# DA1470x register map
Vendor: Dialog; Series: DA1470x; File version: 1.2
CPU: CM33 r0p2, little endian, MPU, FPU, DSP, VTOR, 4 interrupt priority bits
Registers are 32-bit, read-write, reset 0x0 unless marked. A register's access mark holds for its fields unless they carry their own. Offsets are from the block's base; [hi:lo] are bit positions; {n}, {i} and the like mark numbered series; <NAME> marks a mode.

## CRG_TOP — CRG_TOP registers
Base 0x50000000
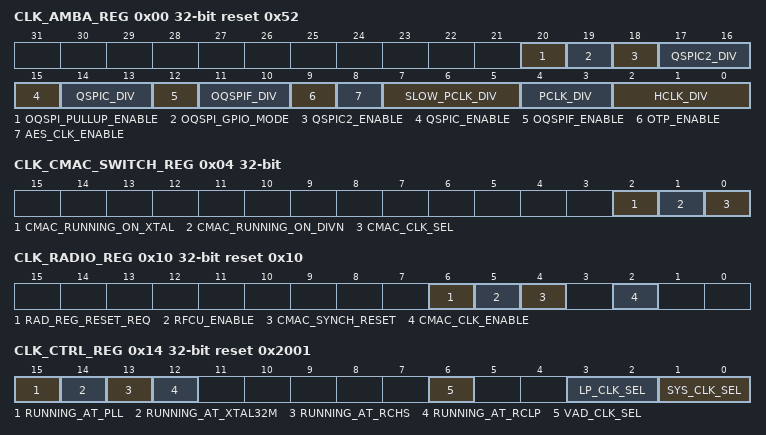
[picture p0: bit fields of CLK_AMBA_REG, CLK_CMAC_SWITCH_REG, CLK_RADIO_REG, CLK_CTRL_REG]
0x00 CLK_AMBA_REG reset 0x52 — HCLK, PCLK, divider and clock gates
  [20] OQSPI_PULLUP_ENABLE — Selects pull value when OQSPIF_D* pads are not output. 0: The pads are pull-down 1: The pads are pull-up (to V18F)
  [19] OQSPI_GPIO_MODE — If this bit is set, the upper 4 pins of the OQSPIF controller can be used as GPIO, P2_07 to P2_04. In this mode, the OQSPIF controller should be restricted to QUAD mode or less. Note: the supply remains V18F, so if the supply is off, the pads become floating.
  [18] QSPIC2_ENABLE — Clock enable for QSPI RAM controller
  [17:16] QSPIC2_DIV — Clock divider setting. 0b00: divide by 1 0b01: divide by 2 0b10: divide by 4 0b11: divide by 8
  [15] QSPIC_ENABLE — Clock enable for QSPI FLASH2 controller
  [14:13] QSPIC_DIV — Clock divider setting. 0b00: divide by 1 0b01: divide by 2 0b10: divide by 4 0b11: divide by 8
  [12] OQSPIF_ENABLE — Clock enable for Octal SPI controller
  [11:10] OQSPIF_DIV — Clock divider setting. 0b00: divide by 1 0b01: divide by 2 0b10: divide by 4 0b11: divide by 8
  [9] OTP_ENABLE — Clock enable for OTP controller
  [8] AES_CLK_ENABLE — Clock enable for AES crypto block
  [7:5] SLOW_PCLK_DIV — Slow-APB interface clock, derived from DIVN_CLK: 0b000: divide divn_clk by 1 0b001: divide divn_clk by 2 0b010: divide divn_clk by 4 0b011: divide divn_clk by 8 0b1xx: divide divn_clk by 16
  [4:3] PCLK_DIV — Fast-APB interface clock, Cascaded with HCLK: 0b00: divide hclk by 1 0b01: divide hclk by 2 0b10: divide hclk by 4 0b11: divide hclk by 8
  [2:0] HCLK_DIV — AHB interface and microprocessor clock. Source clock divided by: 0b000: divide clk by 1 0b001: divide clk by 2 0b010: divide clk by 4 0b011: divide clk by 8 0b1xx: divide clk by 16
0x04 CLK_CMAC_SWITCH_REG — Clock switching register for CMAC clock domain
  [2] CMAC_RUNNING_ON_XTAL ro — This bit is '1' when the CMAC_CLK is enabled, and the switch is set in the XTAL32M position.
  [1] CMAC_RUNNING_ON_DIVN ro — This bit is '1' when the CMAC_CLK is enabled, and the switch is set in the DIVN_CLK position.
  [0] CMAC_CLK_SEL — Selects the clock source of the CMAC_CLK. 0: DIVN_CLK is selected 1: XTAL32M is selected. Note: this bitfield can only be set to '1' when the PD_RAD domain is on (RAD_IS_UP), and will be automatically reset to '0' when the PD_RAD power domain turns off.
0x0C RST_CTRL_REG — Reset control register
  [0] SYS_CACHE_FLUSH_WITH_SW_RESET — 0: Flush the System Cache memory only at HW reset. 1: Flush the System Cache memory also at SW reset.
0x10 CLK_RADIO_REG reset 0x10 — Radio PLL control register
  [6] RAD_REG_RESET_REQ — Reset request for registers of the radio PHY.
  [5] RFCU_ENABLE — Enable the RF control Unit clock
  [4] CMAC_SYNCH_RESET — Force synchronous reset to CMAC core and Sleep Timer. Its effective only when both Radio and Timer Power Domains are powered and the clocks are enabled. CMAC CPU and CMAC registers, including the retained ones, will be reset. It should be kept in reset for enough time to make sure that it will be captured by CMAC, Low Power and APB clocks.
  [2] CMAC_CLK_ENABLE — Enables the clock
0x14 CLK_CTRL_REG reset 0x2001 — Clock control register
  [15] RUNNING_AT_PLL ro — Indicates that the PLL clock is used as clock, and may not be switched off
  [14] RUNNING_AT_XTAL32M ro — Indicates that the XTAL32M clock is used as clock, and may not be switched off
  [13] RUNNING_AT_RCHS ro — Indicates that the RCHS clock is used as clock
  [12] RUNNING_AT_RCLP ro — Indicates that the RCLP_CLK is being used as clock
  [6] VAD_CLK_SEL — Selects the clock for the VAD. 0: Select RCLP clock (normalized for ~32KHz) 1: Select XTAL32K
  [3:2] LP_CLK_SEL — Sets the clock source of the LowerPower clock 0x0: RC32K 0x1: RCX 0x2: XTAL32K through the oscillator with an external Crystal. 0x3: XTAL32K through an external square wave generator (set PID of GPIO to FUNC_GPIO)
  [1:0] SYS_CLK_SEL — Selects the clock source. 0x0 : XTAL32M 0x1 : RCHS 0x2 : The Low Power clock is used 0x3 : The PLL160Mhz is used Note: switching to/from PLL may only be done from/to XTAL32M.
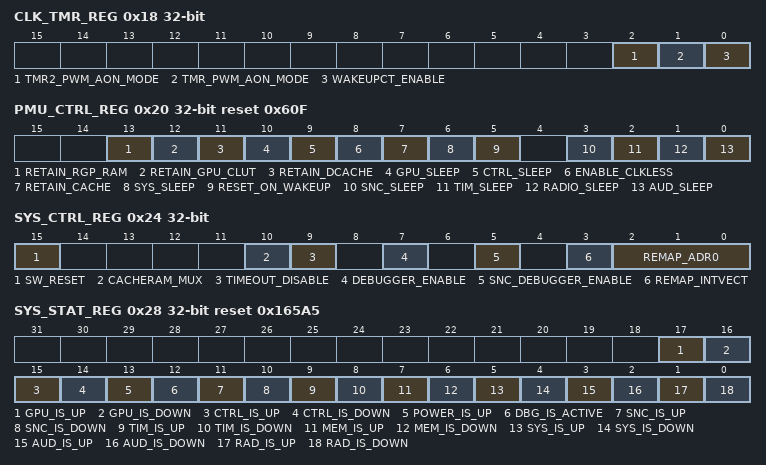
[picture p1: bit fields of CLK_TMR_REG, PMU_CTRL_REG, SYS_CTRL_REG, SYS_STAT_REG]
0x18 CLK_TMR_REG — Clock control for the timers
  [2] TMR2_PWM_AON_MODE — Maps Timer2_pwm onto P1_17. This state is preserved during deep sleep, to allow PWM output on the pad during deep sleep.
  [1] TMR_PWM_AON_MODE — Maps Timer1_pwm onto P1_00 This state is preserved during deep sleep, to allow PWM output on the pad during deep sleep.
  [0] WAKEUPCT_ENABLE — Enables the clock
0x1C CLK_SWITCH2XTAL_REG — Switches clock from RC32M to XTAL32M
  [0] SWITCH2XTAL wo — When writing to this register, the clock switch will happen from RC32M to XTAL32M. If any other clock is selected than RC32M, the selection is discarded.
0x20 PMU_CTRL_REG reset 0x60F — Power Management Unit control register
  [13] RETAIN_RGP_RAM — Retain the R-G-B RAMs inside the LCD display controller
  [12] RETAIN_GPU_CLUT — Retain the GPU CLUT memory
  [11] RETAIN_DCACHE — Selects the retainability of the dcache block while PD_CTRL is off. '1' is retainable, '0' is power gated
  [10] GPU_SLEEP — Put the GPU power domain (PD_GPU) in powerdown
  [9] CTRL_SLEEP — Put the Controller power domain (PD_CTRL) in powerdown
  [8] ENABLE_CLKLESS — Selects the clockless sleep mode. Wakeup is done asynchronously. When set to '1', the lp_clk is stopped during deep sleep, until a wakeup event (not debounced) is detected by the WAKUPCT block. When set to '0', the lp_clk continues running, so the MAC counters keep on running. This mode cannot be combined with regulated sleep, so keep SLEEP_TIMER=0 when using ENABLE_CLKLESS.
  [7] RETAIN_CACHE — Selects the retainability of the cache block during deep sleep. '1' is retainable, '0' is power gated
  [6] SYS_SLEEP — Put the System powerdomain (PD_SYS) in powerdown. If this bit is '1', and there is no pending IRQ in the PDC for the M33, the PD_SYS will be switched off. Wakeup should be handled by the PDC.
  [5] RESET_ON_WAKEUP — Perform a Hardware Reset after waking up. Booter will be started.
  [3] SNC_SLEEP — Put the Communications powerdomain (PD_SNC) in powerdown
  [2] TIM_SLEEP — Put the Timers Powerdomain (PD_TIM) in powerdown.
  [1] RADIO_SLEEP — Put the digital part of the radio, including CMAC (PD_RAD) in powerdown
  [0] AUD_SLEEP — Put the audio power domain (PD_AUD) in powerdown
0x24 SYS_CTRL_REG — System Control register
  [15] SW_RESET wo — Writing a '1' to this bit will generate a SW_RESET.
  [10] CACHERAM_MUX — Controls accessiblity of Cache RAM: 0: the cache controller is bypassed, the cacheRAM is visible in the memory space 1: the cache controller is enabled, the cacheRAM is not visible anymore in the memory space
  [9] TIMEOUT_DISABLE — Disables timeout in Power statemachine. By default, the statemachine continues if after 2 ms the blocks are not started up. This can be read back from ANA_STATUS_REG
  [7] DEBUGGER_ENABLE — Enable the debugger. This bit is set by the booter according to the OTP header. If not set, the SWDIO and SW_CLK can be used as gpio ports.
  [5] SNC_DEBUGGER_ENABLE — Enable the CMAC debugger. If not set, the SWDIO and SW_CLK can be used as gpio ports.
  [3] REMAP_INTVECT — 0: normal operation 1: If ARM is in address range 0 to 0x1FF then the address is remapped to SYS-RAM 0x0080.0000 to 0x0080.01FF. This allows to put the interrupt vector table to be placed in RAM while executing from QSPI.
  [2:0] REMAP_ADR0 — Controls which memory is located at address 0x0000 for execution. 0x0: ROM 0x1: OTP un-cached 0x2: OQSPI FLASH cached (see also the CACHE_FLASH_REG.FLASH_REGION.* descriptions) Note 1: When REMAP_ADR0=0x2, address 0x0 is mapped to FLASH_REGION_BASE + FLASH_REGION_OFFSET<<2. Note 2: When REMAP_ADR0=0x2, the CPU can only access the Flash region [FLASH_REGION_BASE + FLASH_REGION_OFFSET<<2, FLASH_REGION_SIZE] from the 0x16000000 address range. The complete Flash can be accessed via the 0x36000000 address range but only uncached. 0x3: RAMS un-cached 0x4: OQSPI FLASH un-cached (for verification only) 0x5: SYSRAM3 (for SNC-based applications, where SNC uses SYSRAM 1&2) 0x6: Cache Data RAM un-cached (CACHERAM_MUX=0, for testing purposes only) Note 1: DWord (64 bits) access is not supported by the Cache Data RAM interface in mirrored mode (only 32, 16 and 8 bits). Note 2: DMA access is not supported by the Cache Data RAM interface when REMAP_ADR0=0x6.
0x28 SYS_STAT_REG reset 0x165A5 — System status register
  [17] GPU_IS_UP ro — Indicates that PD_GPU is functional
  [16] GPU_IS_DOWN ro — Indicates that PD_GPU is in power down
  [15] CTRL_IS_UP ro — Indicates that PD_CTRL is functional
  [14] CTRL_IS_DOWN ro — Indicates that PD_CTRL is in power down
  [13] POWER_IS_UP ro — Indicates that the Startup statemachine is finished, and all power regulation is in order. In UltraFastWakeup mode, the SW needs to wait for this signal before starting any heavy traffic.
  [12] DBG_IS_ACTIVE ro — Indicates that a debugger is attached.
  [11] SNC_IS_UP ro — Indicates that PD_SNC is functional
  [10] SNC_IS_DOWN ro — Indicates that PD_SNC is in power down
  [9] TIM_IS_UP ro — Indicates that PD_TIM is functional
  [8] TIM_IS_DOWN ro — Indicates that PD_TIM is in power down
  [7] MEM_IS_UP ro — Indicates that PD_MEM is functional
  [6] MEM_IS_DOWN ro — Indicates that PD_MEM is in power down
  [5] SYS_IS_UP ro — Indicates that PD_SYS is functional
  [4] SYS_IS_DOWN ro — Indicates that PD_SYS is in power down
  [3] AUD_IS_UP ro — Indicates that PD_AUD is functional
  [2] AUD_IS_DOWN ro — Indicates that PD_AUD is in power down
  [1] RAD_IS_UP ro — Indicates that PD_RAD is functional
  [0] RAD_IS_DOWN ro — Indicates that PD_RAD is in power down
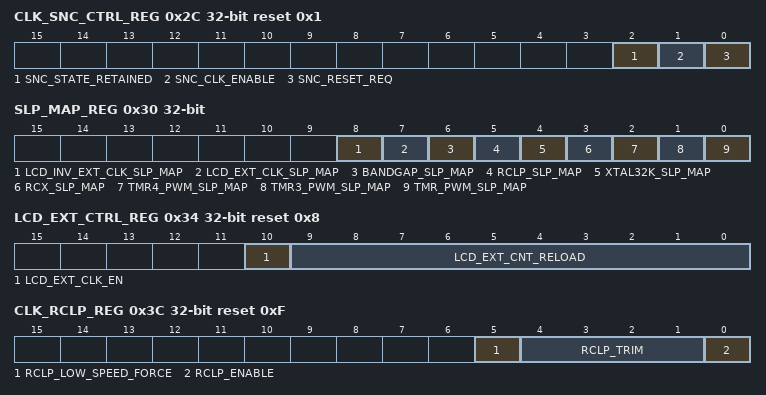
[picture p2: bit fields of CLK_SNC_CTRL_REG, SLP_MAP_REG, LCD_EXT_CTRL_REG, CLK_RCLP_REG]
0x2C CLK_SNC_CTRL_REG reset 0x1
  [2] SNC_STATE_RETAINED — A flag which can be used from FW to indicate that the CPU state has been retained and should be restored during the wakeup sequence (at the beginning of Reset Handler). This flag is retained during the power-down periods.
  [1] SNC_CLK_ENABLE — Clock-enable for the CM0plus in the SNC.
  [0] SNC_RESET_REQ — Force the SNC microprocessor in reset.
0x30 SLP_MAP_REG — Map signals on GPIOs during sleep
  [8] LCD_INV_EXT_CLK_SLP_MAP — Maps inverted LCD_EXT_CLK on P0_10, for LCD XFRP function This state is preserved during deep sleep, to allow pin output toggle on the pad during deep sleep.
  [7] LCD_EXT_CLK_SLP_MAP — Maps LCD_EXT_CLK on P0_19, for LCD VCOM/FRP/EXTCOMIN function This state is preserved during deep sleep, to allow pin output toggle on the pad during deep sleep.
  [6] BANDGAP_SLP_MAP — Setting this bit will: -map bandgap_enable to P0_13 -map (wokenup OR cmac_slp_timer_expire) to P1_06
  [5] RCLP_SLP_MAP — Maps RCLP onto P1_23. This state is preserved during deep sleep, to allow pin output toggle on the pad during deep sleep.
  [4] XTAL32K_SLP_MAP — Maps XTA32k onto P0_31. This state is preserved during deep sleep, to allow pin output toggle on the pad during deep sleep.
  [3] RCX_SLP_MAP — Maps RCX onto P1_22. This state is preserved during deep sleep, to allow pin output toggle on the pad during deep sleep.
  [2] TMR4_PWM_SLP_MAP — Maps Timer4_pwm onto P1_31 This state is preserved during deep sleep, to allow pin output toggle on the pad during deep sleep.
  [1] TMR3_PWM_SLP_MAP — Maps Timer3_pwm onto P1_30 This state is preserved during deep sleep, to allow pin output toggle on the pad during deep sleep.
  [0] TMR_PWM_SLP_MAP — Maps Timer1_pwm onto P0_30 This state is preserved during deep sleep, to allow pin output toggle on the pad during deep sleep.
0x34 LCD_EXT_CTRL_REG reset 0x8
  [10] LCD_EXT_CLK_EN
  [9:0] LCD_EXT_CNT_RELOAD — Reload value for LCD_EXT_CLK generation. When the counter hits 0x0, it is reloaded with LCD_EXT_CNT_RELOAD<<5. So the clock period is F(slp_clk) * 32 * (LCD_EXT_CNT_RELOAD+1) Value 0x0 is not allowed. The LCD_EXT_CLK is generated from the SLP_CLK.
0x3C CLK_RCLP_REG reset 0xF — 32/512 kHz RC oscillator register
  [5] RCLP_LOW_SPEED_FORCE — Forces RCLP in 32kHz mode. If this bit is 0 then RCLP frequency is 512KHz
  [4:1] RCLP_TRIM — 0000 = lowest frequency 0111 = default 1111 = highest frequency
  [0] RCLP_ENABLE — Enables the 32kHz RC oscillator. This bit is gated to '0' automatically when sleep state is entered, and PMU_CTRL_REG.ENABLE_CLKLESS is set to '1'. Do not disable this bit, as deepsleep state is not correctly entered.
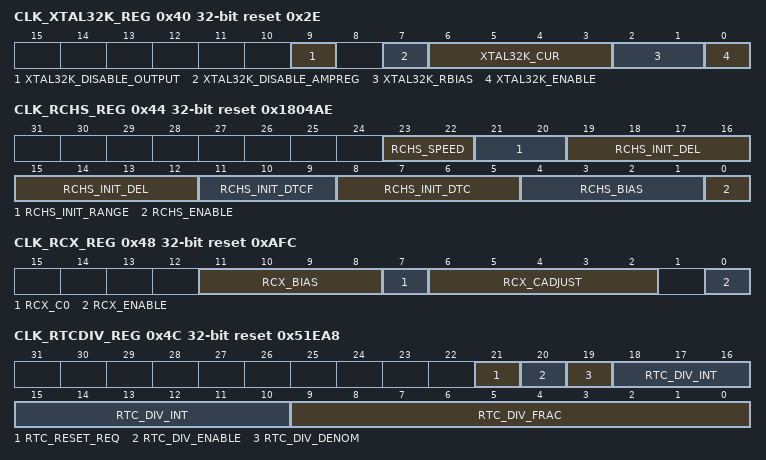
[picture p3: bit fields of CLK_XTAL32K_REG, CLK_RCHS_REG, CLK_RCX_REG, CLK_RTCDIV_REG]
0x40 CLK_XTAL32K_REG reset 0x2E — 32 kHz XTAL oscillator register
  [9] XTAL32K_DISABLE_OUTPUT — Disables output buffer, test only
  [7] XTAL32K_DISABLE_AMPREG — Setting this bit disables the amplitude regulation of the XTAL32kHz oscillator. Set this bit to '1' for an external clock to XTAL32Kp Keep this bit '0' with a crystal between XTAL32Kp and XTAL32Km
  [6:3] XTAL32K_CUR — Bias current for the 32kHz XTAL oscillator. 0000 is minimum, 1111 is maximum, 0011 is default. For each application there is an optimal setting for which the start-up behavior is optimal
  [2:1] XTAL32K_RBIAS — Setting for the bias resistor. 00 is maximum, 11 is minimum. Prefered setting will be provided by Dialog
  [0] XTAL32K_ENABLE — Enables the 32kHz XTAL oscillator
0x44 CLK_RCHS_REG reset 0x1804AE — Fast RC control register
  [23:22] RCHS_SPEED — Selects speed of RCHS output 0b00: 32MHz, by dividing 96 / 3. 0b01: 96MHz, by dividing 96 /1. 0b1x: 64MHz. Note: switching to/from 64MHz requires the RCHS to settle, which can be > 100us. Switching 32 to/from 96MHz does not require settling.
  [21:20] RCHS_INIT_RANGE — Course frequency adjustment
  [19:12] RCHS_INIT_DEL — Fine frequency adjustment
  [11:9] RCHS_INIT_DTCF — Fine duty-cycle adjustment. 0x0: minimum 0x2: default 0x4: maximum 0x5 until 0x7: oscillator does not work
  [8:5] RCHS_INIT_DTC — Course duty-cycle adjustment. 0x0: minimum 0x5: default 0xA: maximum 0xB until 0xF: oscillator does not work
  [4:1] RCHS_BIAS — Bias adjustment
  [0] RCHS_ENABLE — Enables the HighSpeed RC oscillator
0x48 CLK_RCX_REG reset 0xAFC — RCX-oscillator control register
  [11:8] RCX_BIAS — LDO bias current. 0x0: minimum 0xF: maximum
  [7] RCX_C0 — Add unit capacitance to RC-time delay.
  [6:2] RCX_CADJUST — Adjust capacitance part of RC-time delay. 0x00: minimum capacitance 0x1F: maximum capacitance
  [0] RCX_ENABLE — 0: Disable the RCX oscillator (watchdog runs at RCLP) 1: Enable the RCX oscillator (watchdog runs at RCX)
0x4C CLK_RTCDIV_REG reset 0x51EA8 — Divisor for RTC 100Hz clock
  [21] RTC_RESET_REQ — Reset request for the RTC module
  [20] RTC_DIV_ENABLE — Enable for the 100 Hz generation for the RTC block
  [19] RTC_DIV_DENOM — Selects the denominator for the fractional division: 0b0: 1000 0b1: 1024
  [18:10] RTC_DIV_INT — Integer divisor part for RTC 100Hz generation
  [9:0] RTC_DIV_FRAC — Fractional divisor part for RTC 100Hz generation. if RTC_DIV_DENOM=1, <RTC_DIV_FRAC> out of 1024 cycles will divide by <RTC_DIV_INT+1>, the rest is <RTC_DIV_INT> If RTC_DIV_DENOM=0, <RTC_DIV_FRAC> out of 1000 cycles will divide by <RTC_DIV_INT+1>, the rest is <RTC_DIV_INT>
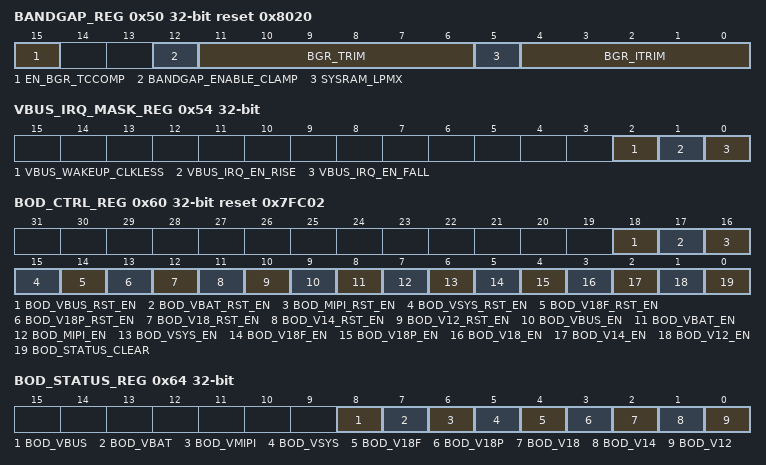
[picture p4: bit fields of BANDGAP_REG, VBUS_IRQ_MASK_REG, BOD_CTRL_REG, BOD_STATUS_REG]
0x50 BANDGAP_REG reset 0x8020 — bandgap trimming
  [15] EN_BGR_TCCOMP — Enable Temperature compensation in the reference current for Charger and LED module. "1" = enabled ( = default setting) "0" = Disabled original currents from BGR are used instead of the Temp-compensated currents
  [12] BANDGAP_ENABLE_CLAMP — Enables a supply clamp inside the bandgap that improves PSRR. Should be enabled by software after cold boot.
  [11:6] BGR_TRIM — Trim register for bandgap
  [5] SYSRAM_LPMX — RAM Transparent Light Sleep (TLS) Core Enable for System RAMs and Cache RAM. Assert low to enable the TLS core feature, which will result in lower leakage current. In case VDD is below 0.81V, it is necessary to hold this pin high to maintain data retention.
  [4:0] BGR_ITRIM — Current trimming for bias
0x54 VBUS_IRQ_MASK_REG — IRQ masking
  [2] VBUS_WAKEUP_CLKLESS — Enables waking up from CLKLESS mode when VBUS becomes available. For the system to wakeup, also the VBUS_IRQ_EN_RISE should be set to trigger the PDC.
  [1] VBUS_IRQ_EN_RISE — Setting this bit to '1' enables VBUS_IRQ generation when the VBUS starts to ramp above threshold
  [0] VBUS_IRQ_EN_FALL — Setting this bit to '1' enables VBUS_IRQ generation when the VBUS starts to fall below threshold
0x58 VBUS_IRQ_CLEAR_REG — Clear pending IRQ register
  [15:0] VBUS_IRQ_CLEAR wo — Writing any value to this register will reset the VBUS_IRQ line
0x60 BOD_CTRL_REG reset 0x7FC02 — Brown Out Detection control register
  [18] BOD_VBUS_RST_EN — If set, generate power-on reset on channel VBUS
  [17] BOD_VBAT_RST_EN — If set, generate power-on reset on channel VBAT.
  [16] BOD_MIPI_RST_EN — If set, generate power-on reset on channel VMIPI
  [15] BOD_VSYS_RST_EN — If set, generate power-on reset on channel VSYS. Bear in mind that there is an additional configurable POR on VSYS rail, check POR_CTRL_REG.
  [14] BOD_V18F_RST_EN — If set, generate power-on reset on channel V18F
  [13] BOD_V18P_RST_EN — If set, generate power-on reset on channel V18P
  [12] BOD_V18_RST_EN — If set, generate power-on reset on channel V18
  [11] BOD_V14_RST_EN — If set, generate power-on reset on channel V14
  [10] BOD_V12_RST_EN — If set, generate power-on reset on channel V12
  [9] BOD_VBUS_EN — Enable brown-out detection for channel VBUS
  [8] BOD_VBAT_EN — Enable brown-out detection for channel VBAT.
  [7] BOD_MIPI_EN — Enable brown-out detection for channel VMIPI
  [6] BOD_VSYS_EN — Enable brown-out detection for channel VSYS. Bear in mind that there is an additional configurable POR on VSYS rail, check POR_CTRL_REG.
  [5] BOD_V18F_EN — Enable brown-out detection for channel V18F
  [4] BOD_V18P_EN — Enable brown-out detection for channel V18P
  [3] BOD_V18_EN — Enable brown-out detection for channel V18
  [2] BOD_V14_EN — Enable brown-out detection for channel V14
  [1] BOD_V12_EN — Enable brown-out detection for channel VDD (V12)
  [0] BOD_STATUS_CLEAR — Clears BOD_STATUS_REG when this bit is 1 for more than 2us. It must be 0 to register BOD events in BOD_STATUS_REG.
0x64 BOD_STATUS_REG
  [8] BOD_VBUS ro — 1: below trigger level (BOD event) 0: above trigger level
  [7] BOD_VBAT ro — 1: below trigger level (BOD event) 0: above trigger level
  [6] BOD_VMIPI ro — 1: below trigger level (BOD event) 0: above trigger level
  [5] BOD_VSYS ro — 1: below trigger level (BOD event) 0: above trigger level
  [4] BOD_V18F ro — 1: below trigger level (BOD event) 0: above trigger level
  [3] BOD_V18P ro — 1: below trigger level (BOD event) 0: above trigger level
  [2] BOD_V18 ro — 1: below trigger level (BOD event) 0: above trigger level
  [1] BOD_V14 ro — 1: below trigger level (BOD event) 0: above trigger level
  [0] BOD_V12 ro — 1: below trigger level (BOD event) 0: above trigger level
0x70 P0_PAD_LATCH_REG reset 0x7FFFFFFF (reset mask 0x7FFFFFFF) — Control the state retention of the GPIO ports
  [31:0] P0_LATCH_EN — Direct write to the individual pad latching signals. Latches the control signals of the pads for state retention in powerdown mode. 0 = Control signals are retained 1 = Latch is transparant, pad can be recontrolled
0x74 P0_SET_PAD_LATCH_REG (reset mask 0x7FFFFFFF) — Control the state retention of the GPIO ports
  [31:0] P0_SET_LATCH_EN rw-once — Direct Set of the marked bits. Reading returns 0x0.
0x78 P0_RESET_PAD_LATCH_REG (reset mask 0x7FFFFFFF) — Control the state retention of the GPIO ports
  [31:0] P0_RESET_LATCH_EN — Direct Reset of the marked bits. Reading returns 0x0.
0x7C P1_PAD_LATCH_REG reset 0x7FFFFFFF (reset mask 0x7FFFFFFF) — Control the state retention of the GPIO ports
  [31:0] P1_LATCH_EN — Direct write to the individual pad latching signals. Latches the control signals of the pads for state retention in powerdown mode. 0 = Control signals are retained 1 = Latch is transparant, pad can be recontrolled
0x80 P1_SET_PAD_LATCH_REG (reset mask 0x7FFFFFFF) — Control the state retention of the GPIO ports
  [31:0] P1_SET_LATCH_EN rw-once — Direct Set of the marked bits. Reading returns 0x0.
0x84 P1_RESET_PAD_LATCH_REG (reset mask 0x7FFFFFFF) — Control the state retention of the GPIO ports
  [31:0] P1_RESET_LATCH_EN — Direct Reset of the marked bits. Reading returns 0x0.
0x88 P2_PAD_LATCH_REG reset 0x7FFF — Control the state retention of the GPIO ports
  [14:0] P2_LATCH_EN — Direct write to the individual pad latching signals. Latches the control signals of the pads for state retention in powerdown mode. 0 = Control signals are retained 1 = Latch is transparant, pad can be recontrolled
0x8C P2_SET_PAD_LATCH_REG — Control the state retention of the GPIO ports
  [14:0] P2_SET_LATCH_EN rw-once — Direct Set of the marked bits. Reading returns 0x0.
0x90 P2_RESET_PAD_LATCH_REG — Control the state retention of the GPIO ports
  [14:0] P2_RESET_LATCH_EN — Direct Reset of the marked bits. Reading returns 0x0.
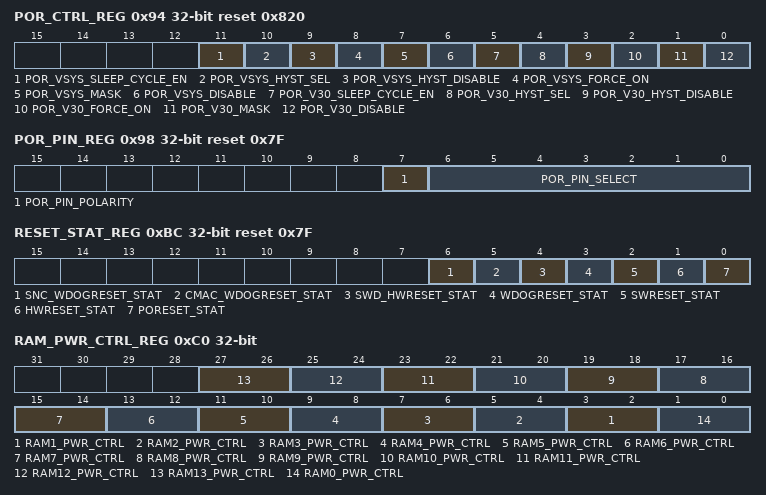
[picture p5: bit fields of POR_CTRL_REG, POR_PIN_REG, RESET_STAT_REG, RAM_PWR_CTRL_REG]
0x94 POR_CTRL_REG reset 0x820 — Controls the POR on VBAT
  [11] POR_VSYS_SLEEP_CYCLE_EN — Enables POR_VSYS during BOD check cycles in sleep (If POR_VSYS_DISABLE = 0)
  [10] POR_VSYS_HYST_SEL — "Selects POR_VSYS threshold level, when hysteresis is disabled (see POR_VSYS_DISABLE) 0: Vthres = VTH_L (low level) 1: Vthres = VTH_H (high level)"
  [9] POR_VSYS_HYST_DISABLE — Disable POR_VSYS hysteresis.
  [8] POR_VSYS_FORCE_ON — FORCE POR_VSYS to be ON (also in SLEEP)
  [7] POR_VSYS_MASK — Mask POR on VSYS
  [6] POR_VSYS_DISABLE — Disable POR_VSYS
  [5] POR_V30_SLEEP_CYCLE_EN — Enables POR_V30 during BOD check cycles in sleep (If POR_V30_DISABLE = 0)
  [4] POR_V30_HYST_SEL — Selects POR_VDDA_3V0 threshold level, when hysteresis is disabled (see POR_VDDA_3V0_HYST_DISABLE) 0: Vthres = VTH_L (low level) 1: Vthres = VTH_H (high level)
  [3] POR_V30_HYST_DISABLE — Disable POR_VDDA_3V0 hysteresis; select level with POR_VDDA_3V0_HYST_SEL
  [2] POR_V30_FORCE_ON — Force POR_VDDA_3V0 always ON, (also in SLEEP)
  [1] POR_V30_MASK — Mask POR_VDDA_3V0
  [0] POR_V30_DISABLE — Disable POR_VDDA_3V0
0x98 POR_PIN_REG reset 0x7F — Selects a GPIO pin for POR generation
  [7] POR_PIN_POLARITY — 0: Active Low 1: Active High Note: This applies only for the GPIO pin. Reset pad is always active High
  [6:0] POR_PIN_SELECT — 0x00: P0_00 ... 0x1f: P0_31 0x20: P1_00 ... 0x3F: P1_31 0x40: P2_00 ... 0x4E: P2_14 0x4F to 0x7E: reserved 0x7F: POR generation disabled
0x9C POR_TIMER_REG reset 0x18 — Time for POR to happen
  [6:0] POR_TIME — Time for the POReset to happen. Formula: Time = POR_TIME x 4096 x RC32 clock period Default value: ~3 seconds
0xBC RESET_STAT_REG reset 0x7F — Reset status register
  [6] SNC_WDOGRESET_STAT — Indicates that a SNC-Watchdog timeout has happened. Note that it is also set when a POReset has happened.
  [5] CMAC_WDOGRESET_STAT — Indicates that a CMAC-Watchdog timeout has happened. Note that it is also set when a POReset has happened.
  [4] SWD_HWRESET_STAT — Indicates that a write to SWD_RESET_REG has happened. Note that it is also set when a POReset has happened.
  [3] WDOGRESET_STAT — Indicates that a Watchdog timeout has happened. Note that it is also set when a POReset has happened.
  [2] SWRESET_STAT — Indicates that a SW Reset has happened
  [1] HWRESET_STAT — Indicates that a HW Reset has happened
  [0] PORESET_STAT — Indicates that a PowerOn Reset has happened. All bitfields of RESET_STAT_REG should be read (in order to check the source of reset) and then cleared to '0', allowing thus the HW to automatically set to '1' the proper bitfields during the next reset event.
0xC0 RAM_PWR_CTRL_REG — Control power state of System RAMS
  [2n+1:2n] RAM{n}_PWR_CTRL (n=1..13) — See description of RAM0_PWR_CTRL.
  [1:0] RAM0_PWR_CTRL — Power state control of the individual RAMs. May only change when the memory isn't accessed. When PD_MEM_IS_UP: 0x0: Normal operation 0x1: Normal operation 0x2: Retained (no access possible) 0x3: Off (memory content corrupted) When PD_MEM_IS_DOWN: 0x0: Retained 0x1: Off (memory content corrupted) 0x2: Retained 0x3: Off (memory content corrupted)
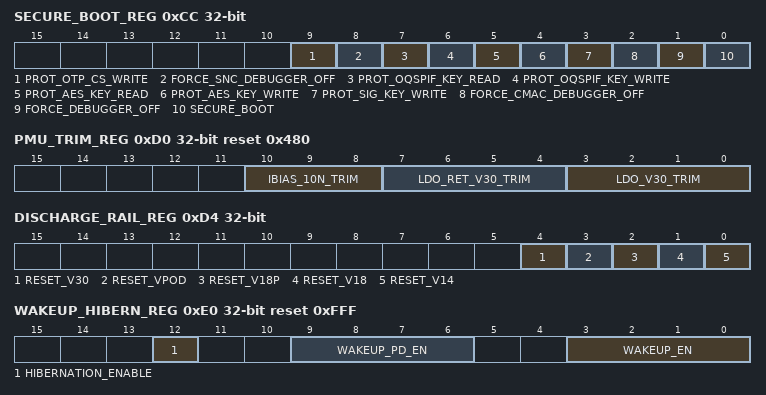
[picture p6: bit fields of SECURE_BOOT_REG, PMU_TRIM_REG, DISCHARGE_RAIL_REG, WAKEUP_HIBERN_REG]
0xCC SECURE_BOOT_REG — Controls secure booting
  [9] PROT_OTP_CS_WRITE — This bit will permanentlly disable any write action to the CS inside the OTP
  [8] FORCE_SNC_DEBUGGER_OFF — This bit will permanently disable the SNC debugger
  [7] PROT_OQSPIF_KEY_READ — This bit will permanently disable CPU read capability at OTP offset 0x00000B00 and for the complete segment
  [6] PROT_OQSPIF_KEY_WRITE — This bit will permanently disable ANY write capability at OTP offset 0x00000B00 and for the complete segment
  [5] PROT_AES_KEY_READ — This bit will permanently disable CPU read capability at OTP offset 0x00000A00 and for the complete segment
  [4] PROT_AES_KEY_WRITE — This bit will permanently disable ANY write capability at OTP offset 0x00000A00 and for the complete segment
  [3] PROT_SIG_KEY_WRITE — This bit will permanently disable ANY write capability at OTP offset 0x000008C0 and for the complete segment
  [2] FORCE_CMAC_DEBUGGER_OFF — This bit will permanently disable the CMAC debugger
  [1] FORCE_DEBUGGER_OFF — Follows the respective OTP flag value. Its value is updated by the BootROM code. 1: The system debugger SWD is totally disabled. 0: The system debugger is enabled with DEBUGGER_ENABLE
  [0] SECURE_BOOT — Follows the respective OTP flag value. Its value is updated by the BootROM code. 1: system is a secure system supporting secure boot 0: system is not supporting secure boot
0xD0 PMU_TRIM_REG reset 0x480
  [10:8] IBIAS_10N_TRIM, [7:4] LDO_RET_V30_TRIM, [3:0] LDO_V30_TRIM
0xD4 DISCHARGE_RAIL_REG — Immediate rail resetting. There is no LDO/DCDC gating
  [4] RESET_V30 — 1: Enables immediate discharging of the V30 rail. Note that the source is not disabled. 0: disable immediate discharging of the V30 rail.
  [3] RESET_VPOD — 1: Enables immediate discharging of the VPOD rail. Note that the source is not disabled. 0: disable immediate discharging of the VPOD rail.
  [2] RESET_V18P — 1: Enables immediate discharging of the V18P rail. Note that the source is not disabled. 0: disable immediate discharging of the V18P rail.
  [1] RESET_V18 — 1: Enables immediate discharging of the V18 rail. Note that the source is not disabled. 0: disable immediate discharging of the V18 rail.
  [0] RESET_V14 — 1: Enables immediate discharging of the V14 rail. Note that the source is not disabled. 0: disable immediate discharging of the V14 rail.
0xE0 WAKEUP_HIBERN_REG reset 0xFFF
  [12] HIBERNATION_ENABLE — Enable hibernation mode
  [9:6] WAKEUP_PD_EN — Enables pulldown for GPIO[n] during hibernation Bit 0: P0_20 Bit 1: P0_29 Bit 2: P1_04 Bit 3: P0_28
  [3:0] WAKEUP_EN — Enables GPIO[n] to wake up from hibernation Bit 0: P0_20 Bit 1: P0_29 Bit 2: P1_04 Bit 3: P0_28
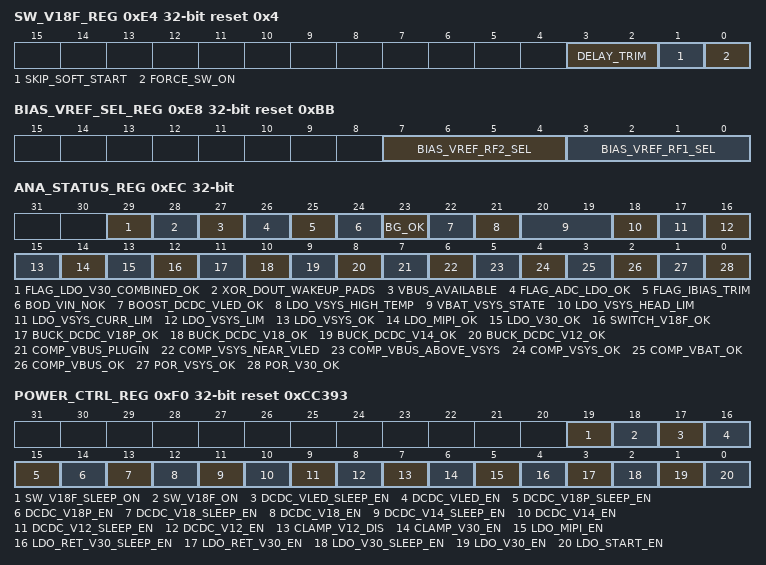
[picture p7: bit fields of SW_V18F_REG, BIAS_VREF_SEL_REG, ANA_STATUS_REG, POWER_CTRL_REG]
0xE4 SW_V18F_REG reset 0x4
  [3:2] DELAY_TRIM — Soft start delay trim
  [1] SKIP_SOFT_START — Skip soft start routine
  [0] FORCE_SW_ON — Forces closing sw_V18f, independent of v18p state
0xE8 BIAS_VREF_SEL_REG reset 0xBB
  [7:4] BIAS_VREF_RF2_SEL — same coding as BIAS_VREF_RF1_SEL.
  [3:0] BIAS_VREF_RF1_SEL — Vref_code | Vref_Voltage (mV) 0:900 1:930 2:960 3:990 4:1020 5:1050 6:1080 7:1110 8:1140 9:1170 10:1200 11:1230 12:1260 13:1290 14:1320 15:1350
0xEC ANA_STATUS_REG — Analog Signals Status Register
  [29] FLAG_LDO_V30_COMBINED_OK ro
  [28] XOR_DOUT_WAKEUP_PADS ro — Will be the result of XOR operation of the hibernation wakeup pads outputs combined. DFT_EN_INPUT_PD_AON_PADS in TEST_CTRL5_REG must be 1.
  [27] VBUS_AVAILABLE ro — High when VBUS > ( VBAT + 150 mV). Hysteresis is approx. 40 mV
  [26] FLAG_ADC_LDO_OK ro — When high, ldo_adc is active
  [25] FLAG_IBIAS_TRIM ro — 10nA Iref trimming, high when on-chip current is larger than reference current
  [24] BOD_VIN_NOK ro — General output of the BOD to indicate that one of the monitored inputs is below the trigger-level.
  [23] BG_OK ro — When high bandgap is active
  [22] BOOST_DCDC_VLED_OK ro — When high, boost dcdc vled is active
  [21] LDO_VSYS_HIGH_TEMP ro — If 1 indicates that temperature of LDO_VSYS is above operating conditions
  [20:19] VBAT_VSYS_STATE ro — 0x0 : Hibernation mode or VBUS-only ( sysbat switch opened). 0x1 : Test mode ( sysbat switch closed). 0x2 : Ideal diode enabled (with VBAT-only or VBUS and VBAT) . 0x3 : Sleep mode (with VBAT-only, sysbat switch closed).
  [18] LDO_VSYS_HEAD_LIM ro — When high, the headroom loop is controlling VSYS
  [17] LDO_VSYS_CURR_LIM ro — When high, the current limiter is controlling VSYS
  [16] LDO_VSYS_LIM ro — When high, the voltage loop is controlling VSYS
  [15] LDO_VSYS_OK ro — When high, LDO_VSYS is in regulating mode
  [14] LDO_MIPI_OK ro — When high, ldo_mipi is active
  [13] LDO_V30_OK ro — When high, ldo_v30 is active
  [12] SWITCH_V18F_OK ro — V18F switch completely closed
  [11] BUCK_DCDC_V18P_OK ro — V18P Rail ok based on DCDC V18P programmed level
  [10] BUCK_DCDC_V18_OK ro — V18 Rail ok based on DCDC V18 programmed level
  [9] BUCK_DCDC_V14_OK ro — V14 Rail ok based on DCDC V14 programmed level
  [8] BUCK_DCDC_V12_OK ro — V12 Rail ok based on DCDC V12 programmed level
  [7] COMP_VBUS_PLUGIN ro — VBUS is connected (VBUS > 2.5V)
  [6] COMP_VSYS_NEAR_VLED ro — BOOST_VLED_SEL=0x0 : VSYS>4.3 BOOST_VLED_SEL=0x1 : VSYS>4.55 BOOST_VLED_SEL=0x2 : VSYS>4.8 BOOST_VLED_SEL=0x3 : VSYS>4.8
  [5] COMP_VBUS_ABOVE_VSYS ro — VBUS>VSYS+0.05V
  [4] COMP_VSYS_OK ro — VSYS> 2.45V
  [3] COMP_VBAT_OK ro — VBAT> 2.7V
  [2] COMP_VBUS_OK ro — 1: VBUS> 4.1V 0: VBUS<3.4V
  [1] POR_VSYS_OK ro
  [0] POR_V30_OK ro
0xF0 POWER_CTRL_REG reset 0xCC393 — Power control register
  [19] SW_V18F_SLEEP_ON — Closes the V18F switch in sleep when DCDC_V18P_SLEEP_EN is 1. See SW_V18F register for more settings.
  [18] SW_V18F_ON — Closes the V18F switch when DCDC_V18P_EN is 1. See SW_V18F register for more settings.
  [17] DCDC_VLED_SLEEP_EN — Enables boost dcdc led rail in sleep mode
  [16] DCDC_VLED_EN — Enables boost dcdc led rail in active mode
  [15] DCDC_V18P_SLEEP_EN — Enables buck dcdc V18p rail in sleep mode
  [14] DCDC_V18P_EN — Enables buck dcdc V18p rail in active mode
  [13] DCDC_V18_SLEEP_EN — Enables buck dcdc V18 rail in sleep mode
  [12] DCDC_V18_EN — Enables buck dcdc V18 rail in active mode
  [11] DCDC_V14_SLEEP_EN — Enables buck dcdc V14 rail in sleep mode
  [10] DCDC_V14_EN — Enables buck dcdc V14 rail in active mode
  [9] DCDC_V12_SLEEP_EN — Enables buck dcdc V12 rail in sleep mode
  [8] DCDC_V12_EN — Enables buck dcdc V12 rail in active mode
  [7] CLAMP_V12_DIS — Disables V12 clamp. During Hibernation, V12 clamp will be enabled regardless of this bit.
  [6] CLAMP_V30_EN — Enables V30 clamp.
  [5] LDO_MIPI_EN — Enables ldo MIPI when DCDC_V18P_EN is 1
  [4] LDO_RET_V30_SLEEP_EN — Enables ldo V30 ret in sleep mode
  [3] LDO_RET_V30_EN — Enables ldo V30 ret in active mode
  [2] LDO_V30_SLEEP_EN — Enables ldo V30 in sleep mode
  [1] LDO_V30_EN — Enables ldo V30 in active mode
  [0] LDO_START_EN — Enables ldo start.
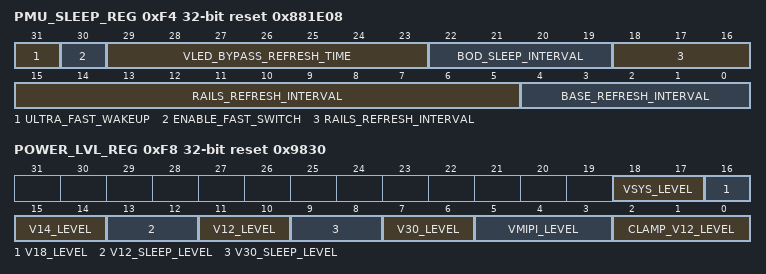
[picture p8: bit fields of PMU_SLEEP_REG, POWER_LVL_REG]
0xF4 PMU_SLEEP_REG reset 0x881E08 (reset mask 0x7FFFFFFF) — Configures the sleep/wakeup strategy
  [31] ULTRA_FAST_WAKEUP — Allows the core to start running on the RC32M while the PMU is still waiting for supplies to settle to the final value. Only use in combination with FAST_WAKEUP and 0.9 V on VDD during sleep.
  [30] ENABLE_FAST_SWITCH — Enables early clock switching upon event detection to speed up wakeup time
  [29:23] VLED_BYPASS_REFRESH_TIME — This setting determines how long the VLED bypass switch is closed when VSYS near VLED flag and VLED VNOK flag are asserted in sleep. Each 1 LSB represents 31.25us. If VLED_BYPASS_REFRESH_TIME(sec) >= BASE_REFRESH_INTERVAL(sec), then VLED bypass switch will remain closed until VLED VNOK flag is asserted, if VSYS near VLED flag was high when going to sleep. If VLED_BYPASS_REFRESH_TIME = 0, then VLED bypass switch will remain opened in sleep independently on the state of VSYS near VLED comparator, and will only be closed if needed during the boost refresh cycles.
  [22:19] BOD_SLEEP_INTERVAL — "This is the interval at which the BOD comparators/POR will be checked during sleep. Value represents RAILS_REFRESH_INTERVAL times-> BOD and POR are checked every(sec)=BASE_REFRESH_INTERVAL(sec)*RAILS_REFRESH_INTERVAL*BOD_SLEEP_INTERVAL If 0, BOD/POR will not be checked in sleep."
  [18:5] RAILS_REFRESH_INTERVAL — This is the interval at which the power rails reference voltage will be refreshed during sleep. Value represents BASE_REFRESH_INTERVAL times-> Rails refresh every(sec)=BASE_REFRESH_INTERVAL(sec)*RAILS_REFRESH_INTERVAL. If 0, then voltage reference will not be refreshed in sleep, and BOD/POR will not be checked in sleep.
  [4:0] BASE_REFRESH_INTERVAL — This sets the base time for calculating the intervals at which PMU refreshes during sleep. In addition, if DCDC_VLED_SLEEP_EN=1, this will be the VLED refresh interval. Each 1 LSB represents 0.125ms. Thus, max base time = 3.875ms. If 0, then there will not be any refresh cycle in SLEEP.
0xF8 POWER_LVL_REG reset 0x9830
  [18:17] VSYS_LEVEL — Level setting for VSYS rail when ldo_vsys is enabled (COMP_VBUS_OK & COMP_VBUS_ABOVE_VSYS): 0=4.8V 1=4.6V 2=4.4V 3=4.2V
  [16] V18_LEVEL — Level setting for V18 rail: 0=1.8V 1=1.2V
  [15:14] V14_LEVEL — Level setting for V14 rail: 0=1.2V 1=1.3V 2=1.4V 3=1.5V
  [13:12] V12_SLEEP_LEVEL — Level setting for V12 rail in sleep: 0=0.75V 1=0.9V 2=1.2V 3=reserved
  [11:10] V12_LEVEL — Level setting for V12 rail: 0=0.75V 1=0.9V 2=1.2V 3=reserved
  [9:8] V30_SLEEP_LEVEL — Level setting for V30 in sleep: 0x0: 3.0V 0x1: reserved 0x2: 3.3V 0x3: 3.3V
  [7:6] V30_LEVEL — Level setting for V30: 0x0: 3.0V 0x1: reserved 0x2: 3.3V 0x3: 3.3V
  [5:3] VMIPI_LEVEL — LDO MIPI level: 0.9V+0.05V*LDO_MIPI_LEVEL. Default=1.2V
  [2:0] CLAMP_V12_LEVEL — Level setting for V12 clamp, retained in hibernation (only V12 source in Hibernation). Typical output voltages (not regulated):
